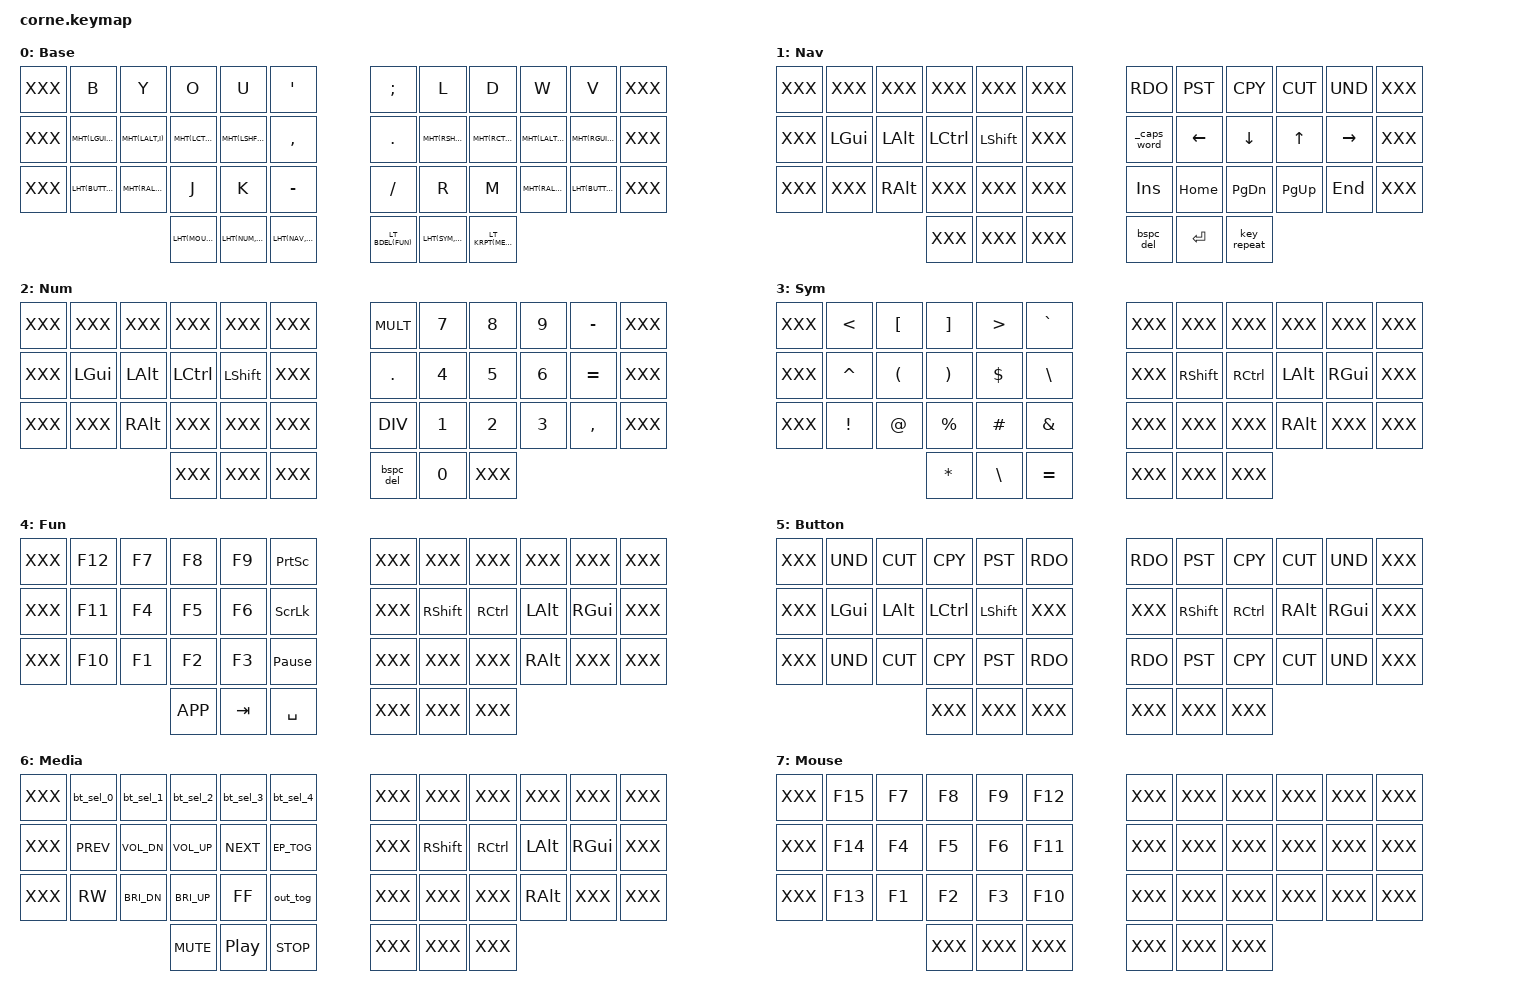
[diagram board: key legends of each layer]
#include "corne.h"

#include "macros.dtsi"
#include "combos.dtsi"
#include "behaviours.dtsi"

/ {
     // chosen {
     //     zmk,physical-layout = &foostan_corne_5col_layout;
     // };

    keymap {
        compatible = "zmk,keymap";

        // Engram (https://engram.dev)
        // -----------------------------------------------------------------------------
        // | [/{ |  1  |  2  |  3  |  4  |  5  | |  6  |  7  |  8  |  9  |  0  | ]/} |
        // | XXX |  B  |  Y  |  O  |  U  | '/( | | "/) |  L  |  D  |  W  |  V  |  Z  |
        // | XXX |  C  |  I  |  E  |  A  | ,/; | | ./: |  H  |  T  |  S  |  N  |  Q  |
        // | XXX |  G  |  X  |  J  |  K  | -/_ | | ?/! |  R  |  M  |  F  |  P  | XXX |
        // |                 | ESC | TAB | SPC | | RET | BCK | DEL |                 |
        // -----------------------------------------------------------------------------
        base {
            display-name = "Base";
            bindings = <
                // Engram (https://engram.dev) Modified
                // ╭─────────────┬─────────────┬─────────────┬─────────────┬─────────────┬─────────────╮   ╭─────────────┬─────────────┬─────────────┬─────────────┬─────────────┬─────────────╮
                    XXX           &kp B         &kp Y         &kp O         &kp U         &kp SQT           &kp SEMI      &kp L         &kp D         &kp W         &kp V         XXX
                // ├─────────────┼─────────────┼─────────────┼─────────────┼─────────────┼─────────────┤   ├─────────────┼─────────────┼─────────────┼─────────────┼─────────────┼─────────────┤
                    XXX           MHT(LGUI,C)   MHT(LALT,I)   MHT(LCTRL,E)  MHT(LSHFT,A)  &kp COMMA         &kp DOT       MHT(RSHFT,H)  MHT(RCTRL,T)  MHT(LALT,S)   MHT(RGUI,N)   XXX
                // ├─────────────┼─────────────┼─────────────┼─────────────┼─────────────┼─────────────┤   ├─────────────┼─────────────┼─────────────┼─────────────┼─────────────┼─────────────┤
                    XXX           LHT(BUTTON,G) MHT(RALT,X)   &kp J         &kp K         &kp MINUS         &kp SLASH     &kp R         &kp M         MHT(RALT,F)   LHT(BUTTON,P) XXX
                // ╰─────────────┴─────────────┴─────────────┼─────────────┼─────────────┼─────────────┤   ├─────────────┼─────────────┼─────────────┼─────────────┴─────────────┴─────────────╯
                                                              LHT(MOUSE,ESC) LHT(NUM,SPACE) LHT(NAV,TAB)    LT_BDEL(FUN)  LHT(SYM,RET)  LT_KRPT(MEDIA)
                //                                           ╰─────────────┴─────────────┴─────────────╯   ╰─────────────┴─────────────┴─────────────╯
            >;
        };
        nav {
            display-name = "Nav";
            bindings = <
                // ╭─────────────┬─────────────┬─────────────┬─────────────┬─────────────┬─────────────╮   ╭─────────────┬─────────────┬─────────────┬─────────────┬─────────────┬─────────────╮
                    XXX           XXX           XXX           XXX           XXX           XXX               _RDO          _PST          _CPY          _CUT          _UND          XXX
                // ├─────────────┼─────────────┼─────────────┼─────────────┼─────────────┼─────────────┤   ├─────────────┼─────────────┼─────────────┼─────────────┼─────────────┼─────────────┤
                    XXX           &kp LGUI      &kp LALT      &kp LCTRL     &kp LSHFT     XXX               &_caps_word   &kp LEFT      &kp DOWN      &kp UP        &kp RIGHT     XXX
                // ├─────────────┼─────────────┼─────────────┼─────────────┼─────────────┼─────────────┤   ├─────────────┼─────────────┼─────────────┼─────────────┼─────────────┼─────────────┤
                    XXX           XXX           &kp RALT      XXX           XXX           XXX               &kp INS       &kp HOME      &kp PG_DN     &kp PG_UP     &kp END       XXX
                // ╰─────────────┴─────────────┴─────────────┼─────────────┼─────────────┼─────────────┤   ├─────────────┼─────────────┼─────────────┼─────────────┴─────────────┴─────────────╯
                                                              XXX           XXX           XXX               &bspc_del     &kp RET       &key_repeat
                //                                           ╰─────────────┴─────────────┴─────────────╯   ╰─────────────┴─────────────┴─────────────╯
            >;
        };
        num {
            display-name = "Num";
            bindings = <
                // ╭─────────────┬─────────────┬─────────────┬─────────────┬─────────────┬─────────────╮   ╭─────────────┬─────────────┬─────────────┬─────────────┬─────────────┬─────────────╮
                    XXX           XXX           XXX           XXX           XXX           XXX               _MULT         &kp N7        &kp N8        &kp N9        &kp MINUS     XXX
                // ├─────────────┼─────────────┼─────────────┼─────────────┼─────────────┼─────────────┤   ├─────────────┼─────────────┼─────────────┼─────────────┼─────────────┼─────────────┤
                    XXX           &kp LGUI      &kp LALT      &kp LCTRL     &kp LSHFT     XXX               &kp DOT       &kp N4        &kp N5        &kp N6        &kp EQUAL     XXX
                // ├─────────────┼─────────────┼─────────────┼─────────────┼─────────────┼─────────────┤   ├─────────────┼─────────────┼─────────────┼─────────────┼─────────────┼─────────────┤
                    XXX           XXX           &kp RALT      XXX           XXX           XXX               _DIV          &kp N1        &kp N2        &kp N3        &kp COMMA     XXX
                // ╰─────────────┴─────────────┴─────────────┼─────────────┼─────────────┼─────────────┤   ├─────────────┼─────────────┼─────────────┼─────────────┴─────────────┴─────────────╯
                                                              XXX           XXX           XXX               &bspc_del     &kp N0        XXX
                //                                           ╰─────────────┴─────────────┴─────────────╯   ╰─────────────┴─────────────┴─────────────╯
            >;
        };
        sym {
            display-name = "Sym";
            bindings = <
                // ╭─────────────┬─────────────┬─────────────┬─────────────┬─────────────┬─────────────╮   ╭─────────────┬─────────────┬─────────────┬─────────────┬─────────────┬─────────────╮
                    XXX           &kp LT        &kp LBKT      &kp RBKT      &kp GT        &kp GRAVE         XXX           XXX           XXX           XXX           XXX           XXX
                // ├─────────────┼─────────────┼─────────────┼─────────────┼─────────────┼─────────────┤   ├─────────────┼─────────────┼─────────────┼─────────────┼─────────────┼─────────────┤
                    XXX           &kp CARET     &kp LPAR      &kp RPAR      &kp DOLLAR    &kp BSLH          XXX           &kp RSHFT     &kp RCTRL     &kp LALT      &kp RGUI      XXX
                // ├─────────────┼─────────────┼─────────────┼─────────────┼─────────────┼─────────────┤   ├─────────────┼─────────────┼─────────────┼─────────────┼─────────────┼─────────────┤
                    XXX           &kp EXCL      &kp AT        &kp PERCENT   &kp HASH      &kp AMPS          XXX           XXX           XXX           &kp RALT      XXX           XXX
                // ╰─────────────┴─────────────┴─────────────┼─────────────┼─────────────┼─────────────┤   ├─────────────┼─────────────┼─────────────┼─────────────┴─────────────┴─────────────╯
                                                              &kp STAR      &kp BSLH      &kp EQUAL         XXX           XXX           XXX
                //                                           ╰─────────────┴─────────────┴─────────────╯   ╰─────────────┴─────────────┴─────────────╯
            >;
        };
        fun {
            display-name = "Fun";
            bindings = <
                // ╭─────────────┬─────────────┬─────────────┬─────────────┬─────────────┬─────────────╮   ╭─────────────┬─────────────┬─────────────┬─────────────┬─────────────┬─────────────╮
                    XXX           &kp F12       &kp F7        &kp F8        &kp F9        &kp PSCRN         XXX           XXX           XXX           XXX           XXX           XXX
                // ├─────────────┼─────────────┼─────────────┼─────────────┼─────────────┼─────────────┤   ├─────────────┼─────────────┼─────────────┼─────────────┼─────────────┼─────────────┤
                    XXX           &kp F11       &kp F4        &kp F5        &kp F6        &kp SLCK          XXX           &kp RSHFT     &kp RCTRL     &kp LALT      &kp RGUI      XXX
                // ├─────────────┼─────────────┼─────────────┼─────────────┼─────────────┼─────────────┤   ├─────────────┼─────────────┼─────────────┼─────────────┼─────────────┼─────────────┤
                    XXX           &kp F10       &kp F1        &kp F2        &kp F3        &kp PAUSE_BREAK   XXX           XXX           XXX           &kp RALT      XXX           XXX
                // ╰─────────────┴─────────────┴─────────────┼─────────────┼─────────────┼─────────────┤   ├─────────────┼─────────────┼─────────────┼─────────────┴─────────────┴─────────────╯
                                                              &kp K_APP     &kp TAB       &kp SPACE         XXX           XXX           XXX
                //                                           ╰─────────────┴─────────────┴─────────────╯   ╰─────────────┴─────────────┴─────────────╯
            >;
        };
        button {
            // TODO: Add mouse buttons to thumb keys
            display-name = "Button";
            bindings = <
                // ╭─────────────┬─────────────┬─────────────┬─────────────┬─────────────┬─────────────╮   ╭─────────────┬─────────────┬─────────────┬─────────────┬─────────────┬─────────────╮
                    XXX           _UND          _CUT          _CPY          _PST          _RDO              _RDO          _PST          _CPY          _CUT          _UND          XXX
                // ├─────────────┼─────────────┼─────────────┼─────────────┼─────────────┼─────────────┤   ├─────────────┼─────────────┼─────────────┼─────────────┼─────────────┼─────────────┤
                    XXX           &kp LGUI      &kp LALT      &kp LCTRL     &kp LSHFT     XXX               XXX           &kp RSHFT     &kp RCTRL     &kp RALT      &kp RGUI      XXX
                // ├─────────────┼─────────────┼─────────────┼─────────────┼─────────────┼─────────────┤   ├─────────────┼─────────────┼─────────────┼─────────────┼─────────────┼─────────────┤
                    XXX           _UND          _CUT          _CPY          _PST          _RDO              _RDO          _PST          _CPY          _CUT          _UND          XXX
                // ╰─────────────┴─────────────┴─────────────┼─────────────┼─────────────┼─────────────┤   ├─────────────┼─────────────┼─────────────┼─────────────┴─────────────┴─────────────╯
                                                              XXX           XXX           XXX               XXX           XXX           XXX
                //                                           ╰─────────────┴─────────────┴─────────────╯   ╰─────────────┴─────────────┴─────────────╯
            >;
        };
        media {
            display-name = "Media";
            bindings = <
                // ╭─────────────┬─────────────┬─────────────┬─────────────┬─────────────┬─────────────╮   ╭─────────────┬─────────────┬─────────────┬─────────────┬─────────────┬─────────────╮
                    XXX           &bt_sel_0     &bt_sel_1     &bt_sel_2     &bt_sel_3     &bt_sel_4         XXX           XXX           XXX           XXX           XXX           XXX
                // ├─────────────┼─────────────┼─────────────┼─────────────┼─────────────┼─────────────┤   ├─────────────┼─────────────┼─────────────┼─────────────┼─────────────┼─────────────┤
                    XXX           &kp C_PREV    &kp C_VOL_DN  &kp C_VOL_UP  &kp C_NEXT    _EP_TOG           XXX           &kp RSHFT     &kp RCTRL     &kp LALT      &kp RGUI      XXX
                // ├─────────────┼─────────────┼─────────────┼─────────────┼─────────────┼─────────────┤   ├─────────────┼─────────────┼─────────────┼─────────────┼─────────────┼─────────────┤
                    XXX           &kp C_RW      &kp C_BRI_DN  &kp C_BRI_UP  &kp C_FF      &out_tog          XXX           XXX           XXX           &kp RALT      XXX           XXX
                // ╰─────────────┴─────────────┴─────────────┼─────────────┼─────────────┼─────────────┤   ├─────────────┼─────────────┼─────────────┼─────────────┴─────────────┴─────────────╯
                                                              &kp C_MUTE    &kp C_PP      &kp C_STOP        XXX           XXX           XXX
                //                                           ╰─────────────┴─────────────┴─────────────╯   ╰─────────────┴─────────────┴─────────────╯
            >;
        };
        mouse {
            display-name = "Mouse";
            bindings = <
                // ╭─────────────┬─────────────┬─────────────┬─────────────┬─────────────┬─────────────╮   ╭─────────────┬─────────────┬─────────────┬─────────────┬─────────────┬─────────────╮
                    XXX           &kp F15       &kp F7        &kp F8        &kp F9        &kp F12           XXX           XXX           XXX           XXX           XXX           XXX
                // ├─────────────┼─────────────┼─────────────┼─────────────┼─────────────┼─────────────┤   ├─────────────┼─────────────┼─────────────┼─────────────┼─────────────┼─────────────┤
                    XXX           &kp F14       &kp F4        &kp F5        &kp F6        &kp F11           XXX           XXX           XXX           XXX           XXX           XXX
                // ├─────────────┼─────────────┼─────────────┼─────────────┼─────────────┼─────────────┤   ├─────────────┼─────────────┼─────────────┼─────────────┼─────────────┼─────────────┤
                    XXX           &kp F13       &kp F1        &kp F2        &kp F3        &kp F10           XXX           XXX           XXX           XXX           XXX           XXX
                // ╰─────────────┴─────────────┴─────────────┼─────────────┼─────────────┼─────────────┤   ├─────────────┼─────────────┼─────────────┼─────────────┴─────────────┴─────────────╯
                                                              XXX           XXX           XXX               XXX           XXX           XXX
                //                                           ╰─────────────┴─────────────┴─────────────╯   ╰─────────────┴─────────────┴─────────────╯
            >;
        };
    };
};
